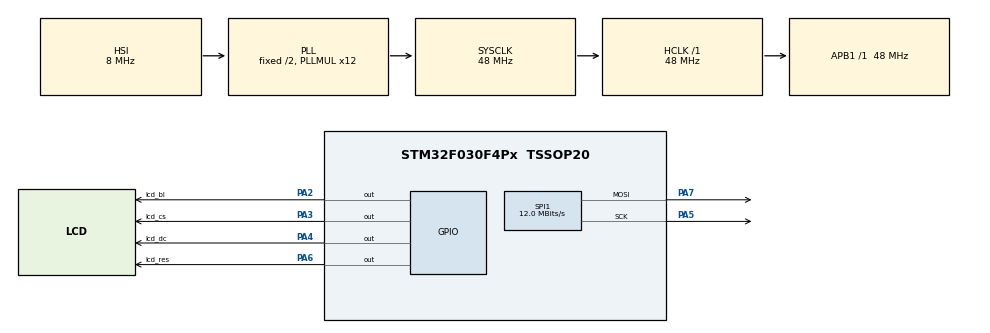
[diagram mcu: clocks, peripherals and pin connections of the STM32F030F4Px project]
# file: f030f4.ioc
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Mcu.Family=STM32F0
Mcu.Name=STM32F030F4Px
Mcu.Package=TSSOP20
PA2.GPIO_Label=lcd_bl
PA2.Signal=GPIO_Output
PA3.GPIO_Label=lcd_cs
PA3.Signal=GPIO_Output
PA4.GPIO_Label=lcd_dc
PA4.Signal=GPIO_Output
PA5.Mode=TX_Only_Simplex_Unidirect_Master
PA5.Signal=SPI1_SCK
PA6.GPIO_Label=lcd_res
PA6.Signal=GPIO_Output
PA7.Mode=TX_Only_Simplex_Unidirect_Master
PA7.Signal=SPI1_MOSI
ProjectManager.HeapSize=0x200
ProjectManager.StackSize=0x400
ProjectManager.TargetToolchain=STM32CubeIDE
RCC.AHBFreq_Value=48000000
RCC.APB1Freq_Value=48000000
RCC.APB1TimFreq_Value=48000000
RCC.HCLKFreq_Value=48000000
RCC.PLLMUL=RCC_PLL_MUL12
RCC.SYSCLKFreq_VALUE=48000000
RCC.SYSCLKSource=RCC_SYSCLKSOURCE_PLLCLK
SPI1.BaudRatePrescaler=SPI_BAUDRATEPRESCALER_4
SPI1.CalculateBaudRate=12.0 MBits/s
SPI1.DataSize=SPI_DATASIZE_8BIT
SPI1.Direction=SPI_DIRECTION_2LINES
SPI1.Mode=SPI_MODE_MASTER
SPI1.NSSPMode=SPI_NSS_PULSE_DISABLE
SPI1.VirtualType=VM_MASTER
board=custom

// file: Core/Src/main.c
/* USER CODE BEGIN Header */
/**
  ******************************************************************************
  * @file           : main.c
  * @brief          : Main program body
  ******************************************************************************
  * @attention
  *
  * Copyright (c) 2023 STMicroelectronics.
  * All rights reserved.
  *
  * This software is licensed under terms that can be found in the LICENSE file
  * in the root directory of this software component.
  * If no LICENSE file comes with this software, it is provided AS-IS.
  *
  ******************************************************************************
  */
/* USER CODE END Header */
#include "main.h"

/* USER CODE BEGIN Includes */
extern void LCD_1in28_test();
/* USER CODE END Includes */

SPI_HandleTypeDef hspi1;

void SystemClock_Config(void);
static void MX_GPIO_Init(void);
static void MX_SPI1_Init(void);

int main(void)
{

  /* MCU Configuration--------------------------------------------------------*/

  /* Reset of all peripherals, Initializes the Flash interface and the Systick. */
  HAL_Init();

  /* Configure the system clock */
  SystemClock_Config();

  /* Initialize all configured peripherals */
  MX_GPIO_Init();
  MX_SPI1_Init();
  /* USER CODE BEGIN 2 */
  LCD_1in28_test();

  /* USER CODE END 2 */

  /* Infinite loop */
  while (1)
  {

    /* USER CODE BEGIN 3 */
	  Paint_Clear(rand());
  }
  /* USER CODE END 3 */
}

void SystemClock_Config(void)
{
  RCC_OscInitTypeDef RCC_OscInitStruct = {0};
  RCC_ClkInitTypeDef RCC_ClkInitStruct = {0};

  /** Initializes the RCC Oscillators according to the specified parameters
  * in the RCC_OscInitTypeDef structure.
  */
  RCC_OscInitStruct.OscillatorType = RCC_OSCILLATORTYPE_HSI;
  RCC_OscInitStruct.HSIState = RCC_HSI_ON;
  RCC_OscInitStruct.HSICalibrationValue = RCC_HSICALIBRATION_DEFAULT;
  RCC_OscInitStruct.PLL.PLLState = RCC_PLL_ON;
  RCC_OscInitStruct.PLL.PLLSource = RCC_PLLSOURCE_HSI;
  RCC_OscInitStruct.PLL.PLLMUL = RCC_PLL_MUL12;
  RCC_OscInitStruct.PLL.PREDIV = RCC_PREDIV_DIV1;
  if (HAL_RCC_OscConfig(&RCC_OscInitStruct) != HAL_OK)
  {
    Error_Handler();
  }

  /** Initializes the CPU, AHB and APB buses clocks
  */
  RCC_ClkInitStruct.ClockType = RCC_CLOCKTYPE_HCLK|RCC_CLOCKTYPE_SYSCLK
                              |RCC_CLOCKTYPE_PCLK1;
  RCC_ClkInitStruct.SYSCLKSource = RCC_SYSCLKSOURCE_PLLCLK;
  RCC_ClkInitStruct.AHBCLKDivider = RCC_SYSCLK_DIV1;
  RCC_ClkInitStruct.APB1CLKDivider = RCC_HCLK_DIV1;

  if (HAL_RCC_ClockConfig(&RCC_ClkInitStruct, FLASH_LATENCY_1) != HAL_OK)
  {
    Error_Handler();
  }
}

static void MX_SPI1_Init(void)
{

  /* SPI1 parameter configuration*/
  hspi1.Instance = SPI1;
  hspi1.Init.Mode = SPI_MODE_MASTER;
  hspi1.Init.Direction = SPI_DIRECTION_2LINES;
  hspi1.Init.DataSize = SPI_DATASIZE_8BIT;
  hspi1.Init.CLKPolarity = SPI_POLARITY_LOW;
  hspi1.Init.CLKPhase = SPI_PHASE_1EDGE;
  hspi1.Init.NSS = SPI_NSS_SOFT;
  hspi1.Init.BaudRatePrescaler = SPI_BAUDRATEPRESCALER_4;
  hspi1.Init.FirstBit = SPI_FIRSTBIT_MSB;
  hspi1.Init.TIMode = SPI_TIMODE_DISABLE;
  hspi1.Init.CRCCalculation = SPI_CRCCALCULATION_DISABLE;
  hspi1.Init.CRCPolynomial = 7;
  hspi1.Init.CRCLength = SPI_CRC_LENGTH_DATASIZE;
  hspi1.Init.NSSPMode = SPI_NSS_PULSE_DISABLE;
  if (HAL_SPI_Init(&hspi1) != HAL_OK)
  {
    Error_Handler();
  }

}

static void MX_GPIO_Init(void)
{
  GPIO_InitTypeDef GPIO_InitStruct = {0};

  /* GPIO Ports Clock Enable */
  __HAL_RCC_GPIOA_CLK_ENABLE();

  /*Configure GPIO pin Output Level */
  HAL_GPIO_WritePin(GPIOA, lcd_bl_Pin|lcd_cs_Pin|lcd_dc_Pin|lcd_res_Pin, GPIO_PIN_RESET);

  /*Configure GPIO pins : lcd_bl_Pin lcd_cs_Pin lcd_dc_Pin lcd_res_Pin */
  GPIO_InitStruct.Pin = lcd_bl_Pin|lcd_cs_Pin|lcd_dc_Pin|lcd_res_Pin;
  GPIO_InitStruct.Mode = GPIO_MODE_OUTPUT_PP;
  GPIO_InitStruct.Pull = GPIO_NOPULL;
  GPIO_InitStruct.Speed = GPIO_SPEED_FREQ_LOW;
  HAL_GPIO_Init(GPIOA, &GPIO_InitStruct);

}

void Error_Handler(void)
{
  __disable_irq();
  while (1)
  {
  }
}
